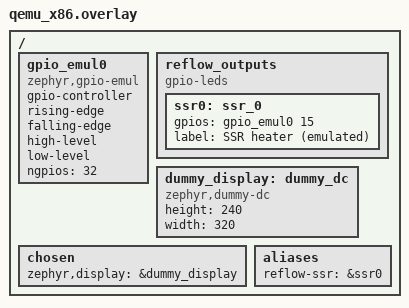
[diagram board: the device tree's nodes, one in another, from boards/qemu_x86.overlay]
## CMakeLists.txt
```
# SPDX-License-Identifier: Apache-2.0

cmake_minimum_required(VERSION 3.20.0)

# The root points at THIS suite's Kconfig, which declares the scene symbol and
# then sources the whole application one - the two properties of RFO-B12 do not
# fit in a single image (see tests/ui/Kconfig).
set(KCONFIG_ROOT ${CMAKE_CURRENT_SOURCE_DIR}/Kconfig)

find_package(Zephyr REQUIRED HINTS $ENV{ZEPHYR_BASE})
project(reflow_ui_tests LANGUAGES C)

set(SRC  ${CMAKE_CURRENT_SOURCE_DIR}/../../src)
set(CORE ${SRC}/core)

# display_ui.c is the subject, and the control core comes along because
# reflow_telemetry_chan is DEFINED in controller.c. Restating the channel here
# would let this suite drift away from the real one - the observer queue depth
# and the publish timeout are exactly what is being measured.
#
# temp_fake.c substitutes ${CORE}/temp.c for the same reason as tests/controller:
# there is no MAX6675 behind an emulated SPI bus.
target_sources(app PRIVATE
  src/main.c
  src/temp_fake.c
  ${SRC}/ui/display_ui.c
  ${CORE}/controller.c
  ${CORE}/heater.c
  ${CORE}/pid.c
  ${CORE}/profile.c
  ${CORE}/tempguard.c
)
target_include_directories(app PRIVATE ${SRC} ${CORE})
```

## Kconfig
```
# SPDX-License-Identifier: Apache-2.0
#
# This suite's Kconfig: one symbol of its own, plus the whole application one.
#
# The symbol exists because the two properties of RFO-B12 do not fit in a single
# image. The display thread reads device_is_ready() ONCE, 500 ms after boot;
# denying readiness after that does not make it reconsider, and denying it
# earlier makes the healthy path unmeasurable. So the difference between the two
# scenes has to exist at boot, and it comes from here.
config REFLOW_TEST_DENY_PANEL
	bool "Deny the chosen display's readiness before any thread runs"
	help
	  A POST_KERNEL SYS_INIT clears the chosen device's readiness so that the
	  display thread finds the panel unavailable - the RFO-B12 scenario.
	  Without it the suite measures the healthy path.

# The application Kconfig, whole: it brings the CONFIG_REFLOW_* menu and ends in
# `source "Kconfig.zephyr"`, so the tree is sourced exactly once. Sourcing
# `Kconfig.zephyr` directly here would lose every application symbol.
source "$(APPLICATION_SOURCE_DIR)/../../Kconfig"
```

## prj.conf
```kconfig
CONFIG_ZTEST=y
CONFIG_ZBUS=y
CONFIG_GPIO=y
CONFIG_GPIO_EMUL=y

# The subject of this suite. DISPLAY and LVGL come in by `select` from the
# application Kconfig, not from here - that is the property the modularity
# matrix protects.
CONFIG_REFLOW_UI_DISPLAY=y

# The panel this suite needs is one whose readiness it can deny, not one that
# draws: the dummy driver gives a real device on a simulated platform.
CONFIG_DUMMY_DISPLAY=y

CONFIG_REFLOW_SHELL=n
CONFIG_REFLOW_UI_INPUT=n
CONFIG_REFLOW_NET=n

# Sizing the application Kconfig ANNOUNCES but does not deliver, pinned here by
# hand (found while building this suite, and now RFO-B49 / #161).
#
# `configdefault LV_Z_MEM_POOL_SIZE default 24576 if REFLOW_UI_DISPLAY` sat in
# the block AFTER `source "Kconfig.zephyr"`, and upstream declares
# `default 2048` unconditionally (zephyr/modules/lvgl/Kconfig.memory:40), so the
# configdefault never applied and the image came out with 2048 - the same
# POSITION defect as RFO-B15 (#121) and RFO-G32 (#122). With 2048 this image does
# not get as far as printing the banner.
#
# Fixing that is not this ticket: it became #161 and is fixed in PR #163. This
# line stays so the suite builds a working image on its own, independently of
# the merge order; once #163 lands it is a redundant assignment of the value the
# Kconfig already supplies, and can go.
CONFIG_LV_Z_MEM_POOL_SIZE=24576
CONFIG_MAIN_STACK_SIZE=8192

# native_sim's counterpart of the line below, and the answer to the SIGABRT that
# held this suite up: enabling DISPLAY on native_sim also turns SDL_DISPLAY on,
# which puts zephyr/boards/native/common/sdl/ in the image - `sdl_init` at
# PRE_BOOT_2 and, the part that mattered, `NATIVE_TASK(sdl_cleanup, ON_EXIT, 2)`
# calling SDL_Quit(). That hook runs inside posix_exit(), which is AFTER ztest
# has printed PROJECT EXECUTION SUCCESSFUL - which is why every assertion passed
# and the process still died with rc=-6, without a line in between.
#
# Measured, not deduced, and the measurement is also the limit of what I can
# claim: built and ran this image on native_sim under WSL and it exits 0 there,
# because that machine has a working video stack. Forcing a headless one
# (SDL_VIDEODRIVER=dummy) makes the SDL display fail loudly instead -
# "Couldn't find matching render driver", rc=1 - which proves the SDL display
# is live in this image and tries to open a window, DUMMY_DISPLAY or not. The
# CI container is the environment that turns that into an abort, so CI is where
# this line is measured.
#
# Turning it off is not a workaround for the runner: the suite wants a device
# whose readiness it can DENY, not a framebuffer, and upstream's own LVGL ztest
# says the same thing on its line 4 (zephyr/tests/lib/gui/lvgl/prj.conf).
CONFIG_SDL_DISPLAY=n

# qemu_x86 has a `qemu,ramfb` node in its devicetree, and enabling DISPLAY turns
# its driver on by itself - which appends `-device ramfb -vga none -display sdl`
# to the QEMU command line. The Zephyr SDK QEMU on Windows has no SDL backend and
# refuses to start without printing a line: that is why the log came back empty
# and twister blew its timeout. This suite wants a device whose readiness it can
# deny, not a framebuffer.
CONFIG_QEMU_RAMFB_DISPLAY=n

# Diagnostics, and they earn their place in a suite nobody can run locally: the
# image passed every assertion and then exited with SIGABRT, printing nothing.
# A silent abort is unreadable from a CI log, and these two make it speak -
# ASSERT turns a kernel __ASSERT into a located message, and immediate logging
# means the last lines are not sitting in a buffer when the process dies.
CONFIG_ASSERT=y
CONFIG_LOG_MODE_IMMEDIATE=y

# LVGL's own log, ON here and only here. The application Kconfig turns it off
# (configdefault LV_USE_LOG default n if REFLOW_UI_DISPLAY), which is right for
# firmware and wrong for the one image built to be diagnosed: LVGL answers a
# failed allocation with LV_ASSERT_MALLOC, and with the log off that assert is a
# silent abort - which is exactly the shape of what this suite is doing
# (PROJECT EXECUTION SUCCESSFUL, then SIGABRT, not one line in between).
CONFIG_LV_USE_LOG=y

# Host-sized stacks. On native_sim the test thread runs on a 64-bit host with
# ZTEST_STACK_SIZE defaulting to 1024 and this file pinning MAIN_STACK_SIZE to
# 2048 - values inherited from an ARM tuning. Simulated memory is free, and a
# stack overflow here would also surface as a silent abort after the assertions
# passed, so the cheap answer is to take it off the table.
CONFIG_ZTEST_STACK_SIZE=8192
```

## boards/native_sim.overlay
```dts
/*
 * SPDX-License-Identifier: Apache-2.0
 *
 * SIMULATION ONLY -- nothing here describes hardware.
 *
 * native_sim already provides a GPIO emulator as gpio0, so unlike the qemu_x86
 * overlay next to this one there is no controller to declare: only the SSR node
 * heater.c needs, and its alias.
 *
 * There is deliberately no thermocouple node. The application's
 * boards/native_sim.overlay declares one, and its own comment records why that
 * is not enough: the emulated bus has no MAX6675 behind it, so
 * reflow_temp_init() fails and the controller latches FAULT_SENSOR before a run
 * can start. This suite links temp_fake.c instead, and the sample comes from
 * the test.
 *
 * native_sim does not run on Windows (PROCESSO.md section 10), which is why the
 * qemu_x86 overlay exists as well. Both platforms build the same source.
 */

#include <zephyr/dt-bindings/gpio/gpio.h>

/ {
	reflow_outputs {
		compatible = "gpio-leds";

		ssr0: ssr_0 {
			gpios = <&gpio0 15 GPIO_ACTIVE_HIGH>;
			label = "SSR heater (emulated)";
		};
	};

	/*
	 * RFO-B12: display_ui.c requires a chosen `zephyr,display` node at
	 * COMPILE time (its own #error). Zephyr's dummy driver provides that node
	 * on a simulated platform and LVGL runs on top of it - this suite does not
	 * need a real panel, it needs a device whose readiness it can deny.
	 */
	dummy_display: dummy_dc {
		compatible = "zephyr,dummy-dc";
		height = <240>;
		width = <320>;
	};

	chosen {
		zephyr,display = &dummy_display;
	};

	aliases {
		reflow-ssr = &ssr0;
	};
};
```

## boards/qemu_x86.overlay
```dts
/*
 * SPDX-License-Identifier: Apache-2.0
 *
 * SIMULATION ONLY -- nothing here describes hardware.
 *
 * Only the SSR gate is declared. There is deliberately no thermocouple node:
 * src/core/temp.c is not in this image, tests/controller/src/temp_fake.c is,
 * and the whole point of the suite is that the reading comes from the test
 * instead of from a bus.
 *
 * qemu_x86 has no GPIO controller of its own, so the emulator is declared here.
 * Pin 15 and GPIO_ACTIVE_HIGH mirror tests/boot and the application overlays.
 */

#include <zephyr/dt-bindings/gpio/gpio.h>

/ {
	gpio_emul0: gpio_emul0 {
		compatible = "zephyr,gpio-emul";
		gpio-controller;
		rising-edge;
		falling-edge;
		high-level;
		low-level;
		#gpio-cells = <2>;
		ngpios = <32>;
		status = "okay";
	};

	reflow_outputs {
		compatible = "gpio-leds";

		ssr0: ssr_0 {
			gpios = <&gpio_emul0 15 GPIO_ACTIVE_HIGH>;
			label = "SSR heater (emulated)";
		};
	};

	/*
	 * RFO-B12: display_ui.c requires a chosen `zephyr,display` node at
	 * COMPILE time (its own #error). Zephyr's dummy driver provides that node
	 * on a simulated platform and LVGL runs on top of it - this suite does not
	 * need a real panel, it needs a device whose readiness it can deny.
	 */
	dummy_display: dummy_dc {
		compatible = "zephyr,dummy-dc";
		height = <240>;
		width = <320>;
	};

	chosen {
		zephyr,display = &dummy_display;
	};

	aliases {
		reflow-ssr = &ssr0;
	};
};
```

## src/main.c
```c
/*
 * SPDX-License-Identifier: Apache-2.0
 *
 * RFO-B12: an unavailable panel must not cost the publish timeout.
 *
 * ZBUS_SUBSCRIBER_DEFINE + ZBUS_CHAN_ADD_OBS attach the observer at COMPILE
 * time, independently of the thread. When device_is_ready() fails the display
 * thread returns - and before this patch the observer stayed attached, enabled,
 * with a queue of 4 and nobody calling zbus_sub_wait(). From the fifth publish
 * on, controller.c's zbus_chan_pub(..., K_MSEC(20)) paid the whole 20 ms, every
 * 500 ms and on every state or fault transition. With a 100 ms control period
 * that is 20 % of overrun - exactly when the panel hardware has failed.
 *
 * TWO SCENES, and the split is forced rather than preferred: the display thread
 * reads device_is_ready() ONCE, 500 ms after boot. Denying readiness after that
 * does not make it reconsider, and denying it earlier makes the healthy path
 * unmeasurable. So the difference lives at boot, in
 * CONFIG_REFLOW_TEST_DENY_PANEL.
 */

#include <zephyr/device.h>
#include <zephyr/init.h>
#include <zephyr/kernel.h>
#include <zephyr/zbus/zbus.h>
#include <zephyr/ztest.h>

#include "app.h"

ZBUS_CHAN_DECLARE(reflow_telemetry_chan);

/* The module under test's observer, so the test can assert about its state. */
extern const struct zbus_observer reflow_display_sub;

static const struct device *const panel = DEVICE_DT_GET(DT_CHOSEN(zephyr_display));

/* The same timeout controller.c publishes with. */
#define PUB_TIMEOUT K_MSEC(20)

/*
 * More than the observer's queue (4). Before the patch it is from the fifth on
 * that the timeout starts being paid in full - measuring six shows the regime
 * rather than the edge.
 */
#define PUBS 6

/*
 * Slack over the 500 ms delay in the display thread's K_THREAD_DEFINE, plus
 * room for ui_build() to finish. 900 ms was not enough on the CI runner: the
 * first publish landed while LVGL was still building the screen and cost 30 ms
 * on the HEALTHY path, which says nothing about this ticket.
 */
#define THREAD_SETTLE K_MSEC(2000)

/*
 * Gap between publishes, and the burst is what was wrong before it existed.
 * controller.c publishes every CONFIG_REFLOW_PUBLISH_PERIOD_MS - 500 ms by
 * default - and on state transitions; it never fires six in a row with no
 * yield. Without a gap the healthy scene measured the test's own scheduling
 * rather than the defect, because the display thread never got to run between
 * publishes.
 *
 * It does NOT soften the defect scene: with the observer enabled and nobody
 * calling zbus_sub_wait(), the queue stays full however long the gap is, so
 * publishes past the fourth still pay the whole timeout.
 */
#define PUB_GAP K_MSEC(20)

#if defined(CONFIG_REFLOW_TEST_DENY_PANEL)
/*
 * POST_KERNEL, before any application thread runs: by the time the display
 * thread wakes up the panel is already unavailable. device_is_ready() reads
 * exactly these two fields (kernel/device.c), so denying them here is the same
 * as a driver whose init failed - with no real panel and no fake driver.
 */
static int deny_panel(void)
{
	panel->state->initialized = false;
	panel->state->init_res = 1;
	return 0;
}
SYS_INIT(deny_panel, POST_KERNEL, CONFIG_KERNEL_INIT_PRIORITY_DEFAULT);
#endif

/* Cost, in ms, of PUBS consecutive publishes with controller.c's timeout. */
static void measure(int64_t *worst, int64_t *total)
{
	struct reflow_telemetry t = {
		.temp_mc = 25000,
		.temp_valid = true,
	};

	*worst = 0;
	*total = 0;

	for (int i = 0; i < PUBS; i++) {
		int64_t t0 = k_uptime_get();
		int64_t dt;

		(void)zbus_chan_pub(&reflow_telemetry_chan, &t, PUB_TIMEOUT);
		dt = k_uptime_get() - t0;

		*total += dt;
		if (dt > *worst) {
			*worst = dt;
		}

		/* Outside the measurement on purpose: this is the control loop's
		 * own cadence, not part of what a publish costs. */
		k_sleep(PUB_GAP);
	}
}

#if defined(CONFIG_REFLOW_TEST_DENY_PANEL)

ZTEST(reflow_ui, test_an_unavailable_panel_does_not_cost_the_timeout)
{
	int64_t worst, total;
	bool enabled = true;

	/* Fixture: the panel really has to be unavailable, or nothing is
	 * measured. */
	zassert_false(device_is_ready(panel),
		      "broken fixture: the panel is ready, so the display thread "
		      "never took the failure branch and this test would pass by "
		      "draining rather than by the patch");

	k_sleep(THREAD_SETTLE);

	zassert_ok(zbus_obs_is_enabled(&reflow_display_sub, &enabled));
	zassert_false(enabled,
		      "the display observer is still enabled after the thread "
		      "gave up; the queue fills at 4 and every publish starts "
		      "paying the whole 20 ms (RFO-B12)");

	measure(&worst, &total);

	zassert_true(worst < 5,
		     "a publish cost %lld ms with the panel unavailable (total "
		     "%lld ms over %d publishes). The observer stayed attached "
		     "with nobody draining it, so zbus_chan_pub() pays the whole "
		     "20 ms timeout - 20 %% of the %d ms control period (RFO-B12)",
		     worst, total, PUBS, CONFIG_REFLOW_CTRL_PERIOD_MS);
}

#else

ZTEST(reflow_ui, test_a_ready_panel_keeps_receiving)
{
	int64_t worst, total;
	bool enabled = false;

	zassert_true(device_is_ready(panel), "fixture: the panel should be ready");

	k_sleep(THREAD_SETTLE);

	/*
	 * The healthy path: the fix disables the observer ONLY in the failure
	 * branch. Somebody disabling it too early, or unconditionally, shows up
	 * here - the UI would stop receiving telemetry with a working panel.
	 */
	zassert_ok(zbus_obs_is_enabled(&reflow_display_sub, &enabled));
	zassert_true(enabled,
		     "the display observer is disabled with the panel READY: the "
		     "RFO-B12 fix leaked into the healthy path and the UI no "
		     "longer receives telemetry");

	/* And the thread is draining, so publishing is cheap here too. */
	measure(&worst, &total);
	zassert_true(worst < 5,
		     "a publish cost %lld ms with the panel ready (total %lld "
		     "ms): the display thread is not draining the queue",
		     worst, total);
}

#endif /* CONFIG_REFLOW_TEST_DENY_PANEL */

ZTEST_SUITE(reflow_ui, NULL, NULL, NULL, NULL, NULL);
```

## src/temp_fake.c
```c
/*
 * SPDX-License-Identifier: Apache-2.0
 *
 * See temp_fake.h. This mirrors the shape of src/core/temp.c — plausibility
 * window, then reflow_spike_filter(), then both the filtered and the raw value
 * out — with the sensor driver replaced by a value the test writes.
 *
 * Keeping the guard rails here rather than returning the injected value
 * straight through is the point: a fake that skipped the filter would let a
 * controller test pass while the real path suppressed the same sample.
 */

#include <errno.h>

#include <zephyr/kernel.h>

#include "temp.h"
#include "tempguard.h"
#include "temp_fake.h"

/*
 * Same window as temp.c, copied rather than shared: the constants are private to
 * temp.c and hoisting them into temp.h is a production change, out of scope here.
 *
 * Say the cost out loud, because no test catches it: widen or narrow the window in
 * temp.c and this fake keeps the old one, silently. Nothing goes red. Unlike the
 * spike filter below -- which calls the real tempguard.c precisely so it cannot
 * drift -- this pair is kept honest by whoever edits temp.c remembering to look
 * here. If the window ever becomes a decision rather than a sanity check, move it
 * to tempguard.c and delete these two lines.
 */
#define TEMP_MIN_MC (-20000)
#define TEMP_MAX_MC (400000)

/*
 * How many times reflow_temp_init() fails before it starts succeeding.
 *
 * Set at BUILD time - see tests/coldstart/CMakeLists.txt - and deliberately
 * not at runtime. The control thread runs its first init from K_THREAD_DEFINE
 * before any test body, and before a `setup` hook too, so a runtime knob could
 * never be set in time to be observed. That is exactly what made the old
 * reflow_temp_fake_fail_init() dead code (RFO-G17). A build-time value is
 * honest: it is fixed before anything runs, which is when it has to be.
 */
#ifndef REFLOW_TEMP_FAKE_INIT_FAILURES
#define REFLOW_TEMP_FAKE_INIT_FAILURES 0
#endif

/* Room temperature: what a healthy sensor reads with the oven cold. */
#define FAKE_IDLE_MC 25000

static struct k_spinlock lock;

static struct {
	struct reflow_spike spike;
	int32_t raw_mc;
	int read_err;
	uint32_t reads;
} fake = {
	.raw_mc = FAKE_IDLE_MC,
};

void reflow_temp_fake_reset(void)
{
	k_spinlock_key_t key = k_spin_lock(&lock);
	int32_t discard;

	reflow_spike_reset(&fake.spike);
	fake.raw_mc = FAKE_IDLE_MC;
	fake.read_err = 0;
	fake.reads = 0;

	/*
	 * Prime the filter with the idle reading, so the fake starts out as a
	 * sensor that has been reading room temperature rather than one that
	 * has never been read. It matters: reflow_spike_filter() accepts its
	 * first sample unconditionally, having nothing to compare against, so
	 * an unprimed fake would swallow the very first injected step -- and a
	 * test that means to exercise the spike rejector would quietly exercise
	 * nothing.
	 */
	(void)reflow_spike_filter(&fake.spike, FAKE_IDLE_MC, &discard);
	k_spin_unlock(&lock, key);
}

void reflow_temp_fake_set_raw_mc(int32_t raw_mc)
{
	k_spinlock_key_t key = k_spin_lock(&lock);

	fake.raw_mc = raw_mc;
	k_spin_unlock(&lock, key);
}

void reflow_temp_fake_fail(int err)
{
	k_spinlock_key_t key = k_spin_lock(&lock);

	fake.read_err = err;
	k_spin_unlock(&lock, key);
}

uint32_t reflow_temp_fake_reads(void)
{
	k_spinlock_key_t key = k_spin_lock(&lock);
	uint32_t n = fake.reads;

	k_spin_unlock(&lock, key);
	return n;
}

/*
 * Fails the first REFLOW_TEMP_FAKE_INIT_FAILURES times, then succeeds.
 *
 * The count is a build-time value and not a runtime knob, and the difference is
 * the whole point: the control thread runs this from K_THREAD_DEFINE at boot,
 * before any ztest body and before a `setup` hook, so nothing set at runtime
 * could ever be in place in time. A knob that looks usable and is not is what
 * RFO-G17 removed from this file; this replaces it with something that is fixed
 * before the first line of the image runs.
 *
 * Default 0, so tests/controller sees a front-end that is simply there. The
 * cold-start image in tests/coldstart builds the same file with 1 and watches
 * the controller recover without a reboot (RFO-B39).
 */
static uint8_t init_failures_left = REFLOW_TEMP_FAKE_INIT_FAILURES;

int reflow_temp_init(void)
{
	k_spinlock_key_t key = k_spin_lock(&lock);

	if (init_failures_left > 0U) {
		init_failures_left--;
		k_spin_unlock(&lock, key);
		return -ENODEV;
	}

	reflow_spike_reset(&fake.spike);
	k_spin_unlock(&lock, key);

	return 0;
}

int reflow_temp_read(int32_t *temp_mc, int32_t *raw_mc)
{
	k_spinlock_key_t key = k_spin_lock(&lock);
	int32_t raw, filtered;
	int ret = 0;

	fake.reads++;

	if (fake.read_err != 0) {
		ret = fake.read_err;
		goto out;
	}

	raw = fake.raw_mc;
	if (raw < TEMP_MIN_MC || raw > TEMP_MAX_MC) {
		ret = -ERANGE;
		goto out;
	}

	(void)reflow_spike_filter(&fake.spike, raw, &filtered);

	*temp_mc = filtered;
	if (raw_mc != NULL) {
		*raw_mc = raw;
	}

out:
	k_spin_unlock(&lock, key);
	return ret;
}
```

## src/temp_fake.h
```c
/*
 * SPDX-License-Identifier: Apache-2.0
 *
 * Injectable thermocouple for the controller suite (RFO-G06).
 *
 * This file provides the temp.h contract in place of src/core/temp.c, so
 * controller.c can be linked into a test image with no MAX6675 and no SPI
 * behind it. The test writes the sample; the controller reads it through
 * exactly the same two functions it calls on hardware.
 *
 * It is deliberately NOT a Kconfig option in the firmware. A production build
 * able to read a made-up temperature is a foot-gun on a mains heater: the
 * substitution happens at link time, in the test's CMakeLists, so no shipped
 * image can contain it.
 */

#ifndef REFLOW_TEMP_FAKE_H_
#define REFLOW_TEMP_FAKE_H_

#include <stdint.h>

/* Healthy sensor at 25 degC, no injected errors, spike history forgotten. */
void reflow_temp_fake_reset(void);

/*
 * The raw sample the next reads return, in milli-degC. It goes through the
 * same plausibility window and the same reflow_spike_filter() that temp.c
 * uses, so a jump larger than REFLOW_SPIKE_MAX_STEP_MC is suppressed here for
 * the same number of samples it would be suppressed on hardware. That is what
 * makes "stuck reading" (RFO-B05) reproducible instead of hand-waved: the test
 * injects a real step, the filter does the sticking.
 */
void reflow_temp_fake_set_raw_mc(int32_t raw_mc);

/*
 * Make reflow_temp_read() return this errno instead of a sample; 0 stops
 * failing. -ENOENT is what the MAX6675 driver reports for an open
 * thermocouple, -EIO what a failed SPI transfer reports.
 */
void reflow_temp_fake_fail(int err);

/* Number of reflow_temp_read() calls since the last reset. */
uint32_t reflow_temp_fake_reads(void);

#endif /* REFLOW_TEMP_FAKE_H_ */
```
